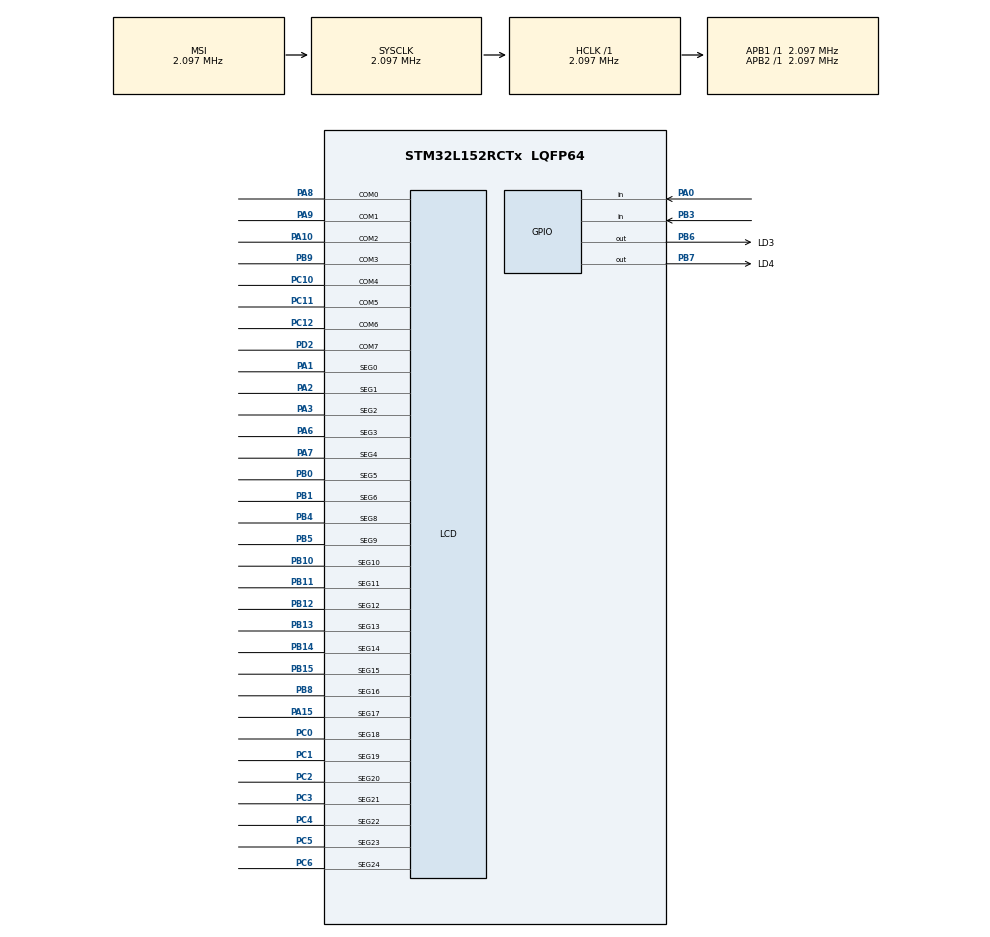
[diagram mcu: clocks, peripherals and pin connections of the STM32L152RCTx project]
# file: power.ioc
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Mcu.Family=STM32L1
Mcu.Name=STM32L152RCTx
Mcu.Package=LQFP64
NVIC.PriorityGroup=NVIC_PRIORITYGROUP_4
PA0-WKUP1.Signal=GPIO_Input
PA1.Mode=SEG0
PA1.Signal=LCD_SEG0
PA10.Mode=1/8 Duty Cycle
PA10.Signal=LCD_COM2
PA15.Mode=SEG17
PA15.Signal=LCD_SEG17
PA2.Mode=SEG1
PA2.Signal=LCD_SEG1
PA3.Mode=SEG2
PA3.Signal=LCD_SEG2
PA6.Mode=SEG3
PA6.Signal=LCD_SEG3
PA7.Mode=SEG4
PA7.Signal=LCD_SEG4
PA8.Mode=1/8 Duty Cycle
PA8.Signal=LCD_COM0
PA9.Mode=1/8 Duty Cycle
PA9.Signal=LCD_COM1
PB0.Mode=SEG5
PB0.Signal=LCD_SEG5
PB1.Mode=SEG6
PB1.Signal=LCD_SEG6
PB10.Mode=SEG10
PB10.Signal=LCD_SEG10
PB11.Mode=SEG11
PB11.Signal=LCD_SEG11
PB12.Mode=SEG12
PB12.Signal=LCD_SEG12
PB13.Mode=SEG13
PB13.Signal=LCD_SEG13
PB14.Mode=SEG14
PB14.Signal=LCD_SEG14
PB15.Mode=SEG15
PB15.Signal=LCD_SEG15
PB3.Signal=GPIO_Input
PB4.Mode=SEG8
PB4.Signal=LCD_SEG8
PB5.Mode=SEG9
PB5.Signal=LCD_SEG9
PB6.GPIO_Label=LD3
PB6.Signal=GPIO_Output
PB7.GPIO_Label=LD4
PB7.Signal=GPIO_Output
PB8.Mode=SEG16
PB8.Signal=LCD_SEG16
PB9.Mode=1/8 Duty Cycle
PB9.Signal=LCD_COM3
PC0.Mode=SEG18
PC0.Signal=LCD_SEG18
PC1.Mode=SEG19
PC1.Signal=LCD_SEG19
PC10.Mode=1/8 Duty Cycle
PC10.Signal=LCD_COM4
PC11.Mode=1/8 Duty Cycle
PC11.Signal=LCD_COM5
PC12.Mode=1/8 Duty Cycle
PC12.Signal=LCD_COM6
PC2.Mode=SEG20
PC2.Signal=LCD_SEG20
PC3.Mode=SEG21
PC3.Signal=LCD_SEG21
PC4.Mode=SEG22
PC4.Signal=LCD_SEG22
PC5.Mode=SEG23
PC5.Signal=LCD_SEG23
PC6.Mode=SEG24
PC6.Signal=LCD_SEG24
PD2.Mode=1/8 Duty Cycle
PD2.Signal=LCD_COM7
ProjectManager.HeapSize=0x200
ProjectManager.StackSize=0x400
ProjectManager.TargetToolchain=STM32CubeIDE
RCC.AHBFreq_Value=2097000
RCC.APB1Freq_Value=2097000
RCC.APB2Freq_Value=2097000
RCC.HSE_VALUE=24000000
RCC.HSI_VALUE=16000000
RCC.LSE_VALUE=32768
RCC.MSI_VALUE=2097000
RCC.SYSCLKFreq_VALUE=2097000
RCC.VCOOutputFreq_Value=48000000
board=custom

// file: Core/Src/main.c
/* USER CODE BEGIN Header */
/**
  ******************************************************************************
  * @file           : main.c
  * @brief          : Main program body
  ******************************************************************************
  * @attention
  *
  * Copyright (c) 2024 STMicroelectronics.
  * All rights reserved.
  *
  * This software is licensed under terms that can be found in the LICENSE file
  * in the root directory of this software component.
  * If no LICENSE file comes with this software, it is provided AS-IS.
  *
  ******************************************************************************
  */
/* USER CODE END Header */
#include "main.h"

LCD_HandleTypeDef hlcd;

void SystemClock_Config(void);
static void MX_GPIO_Init(void);
static void MX_LCD_Init(void);

int main(void)
{

  /* MCU Configuration--------------------------------------------------------*/

  /* Reset of all peripherals, Initializes the Flash interface and the Systick. */
  HAL_Init();

  /* Configure the system clock */
  SystemClock_Config();

  /* Initialize all configured peripherals */
  MX_GPIO_Init();
  MX_LCD_Init();

  /* Infinite loop */
  while (1)
  {

    /* USER CODE BEGIN 3 */
	  HAL_GPIO_WritePin(LD3_GPIO_Port, LD3_Pin, GPIO_PIN_SET);
	//  HAL_GPIO_WritePin(GPIOB, GPIO_PIN_8, GPIO_PIN_SET);
	  HAL_Delay(100);
	  HAL_GPIO_WritePin(LD3_GPIO_Port, LD3_Pin, GPIO_PIN_RESET);
	//  HAL_GPIO_WritePin(GPIOB, GPIO_PIN_8, GPIO_PIN_RESET);
	  HAL_Delay(100);
  }
  /* USER CODE END 3 */
}

void SystemClock_Config(void)
{
  RCC_OscInitTypeDef RCC_OscInitStruct = {0};
  RCC_ClkInitTypeDef RCC_ClkInitStruct = {0};
  RCC_PeriphCLKInitTypeDef PeriphClkInit = {0};

  /** Configure the main internal regulator output voltage
  */
  __HAL_PWR_VOLTAGESCALING_CONFIG(PWR_REGULATOR_VOLTAGE_SCALE1);

  /** Initializes the RCC Oscillators according to the specified parameters
  * in the RCC_OscInitTypeDef structure.
  */
  RCC_OscInitStruct.OscillatorType = RCC_OSCILLATORTYPE_LSI|RCC_OSCILLATORTYPE_MSI;
  RCC_OscInitStruct.LSIState = RCC_LSI_ON;
  RCC_OscInitStruct.MSIState = RCC_MSI_ON;
  RCC_OscInitStruct.MSICalibrationValue = 0;
  RCC_OscInitStruct.MSIClockRange = RCC_MSIRANGE_5;
  RCC_OscInitStruct.PLL.PLLState = RCC_PLL_NONE;
  if (HAL_RCC_OscConfig(&RCC_OscInitStruct) != HAL_OK)
  {
    Error_Handler();
  }

  /** Initializes the CPU, AHB and APB buses clocks
  */
  RCC_ClkInitStruct.ClockType = RCC_CLOCKTYPE_HCLK|RCC_CLOCKTYPE_SYSCLK
                              |RCC_CLOCKTYPE_PCLK1|RCC_CLOCKTYPE_PCLK2;
  RCC_ClkInitStruct.SYSCLKSource = RCC_SYSCLKSOURCE_MSI;
  RCC_ClkInitStruct.AHBCLKDivider = RCC_SYSCLK_DIV1;
  RCC_ClkInitStruct.APB1CLKDivider = RCC_HCLK_DIV1;
  RCC_ClkInitStruct.APB2CLKDivider = RCC_HCLK_DIV1;

  if (HAL_RCC_ClockConfig(&RCC_ClkInitStruct, FLASH_LATENCY_0) != HAL_OK)
  {
    Error_Handler();
  }
  PeriphClkInit.PeriphClockSelection = RCC_PERIPHCLK_RTC|RCC_PERIPHCLK_LCD;
  PeriphClkInit.RTCClockSelection = RCC_RTCCLKSOURCE_LSI;
  PeriphClkInit.LCDClockSelection = RCC_RTCCLKSOURCE_LSI;

  if (HAL_RCCEx_PeriphCLKConfig(&PeriphClkInit) != HAL_OK)
  {
    Error_Handler();
  }
}

static void MX_LCD_Init(void)
{

  hlcd.Instance = LCD;
  hlcd.Init.Prescaler = LCD_PRESCALER_1;
  hlcd.Init.Divider = LCD_DIVIDER_16;
  hlcd.Init.Duty = LCD_DUTY_1_8;
  hlcd.Init.Bias = LCD_BIAS_1_4;
  hlcd.Init.VoltageSource = LCD_VOLTAGESOURCE_INTERNAL;
  hlcd.Init.Contrast = LCD_CONTRASTLEVEL_0;
  hlcd.Init.DeadTime = LCD_DEADTIME_0;
  hlcd.Init.PulseOnDuration = LCD_PULSEONDURATION_0;
  hlcd.Init.MuxSegment = LCD_MUXSEGMENT_DISABLE;
  hlcd.Init.BlinkMode = LCD_BLINKMODE_OFF;
  hlcd.Init.BlinkFrequency = LCD_BLINKFREQUENCY_DIV8;
  if (HAL_LCD_Init(&hlcd) != HAL_OK)
  {
    Error_Handler();
  }

}

static void MX_GPIO_Init(void)
{
  GPIO_InitTypeDef GPIO_InitStruct = {0};

  /* GPIO Ports Clock Enable */
  __HAL_RCC_GPIOC_CLK_ENABLE();
  __HAL_RCC_GPIOA_CLK_ENABLE();
  __HAL_RCC_GPIOB_CLK_ENABLE();
  __HAL_RCC_GPIOD_CLK_ENABLE();

  /*Configure GPIO pin Output Level */
  HAL_GPIO_WritePin(GPIOB, LD3_Pin|LD4_Pin, GPIO_PIN_RESET);

  /*Configure GPIO pin : PA0 */
  GPIO_InitStruct.Pin = GPIO_PIN_0;
  GPIO_InitStruct.Mode = GPIO_MODE_INPUT;
  GPIO_InitStruct.Pull = GPIO_NOPULL;
  HAL_GPIO_Init(GPIOA, &GPIO_InitStruct);

  /*Configure GPIO pin : PB3 */
  GPIO_InitStruct.Pin = GPIO_PIN_3;
  GPIO_InitStruct.Mode = GPIO_MODE_INPUT;
  GPIO_InitStruct.Pull = GPIO_NOPULL;
  HAL_GPIO_Init(GPIOB, &GPIO_InitStruct);

  /*Configure GPIO pins : LD3_Pin LD4_Pin */
  GPIO_InitStruct.Pin = LD3_Pin|LD4_Pin;
  GPIO_InitStruct.Mode = GPIO_MODE_OUTPUT_PP;
  GPIO_InitStruct.Pull = GPIO_NOPULL;
  GPIO_InitStruct.Speed = GPIO_SPEED_FREQ_LOW;
  HAL_GPIO_Init(GPIOB, &GPIO_InitStruct);

}

void Error_Handler(void)
{
  __disable_irq();
  while (1)
  {
  }
}
